# M33 register map
Registers are 32-bit, read-write, reset 0x0 unless marked. A register's access mark holds for its fields unless they carry their own. Offsets are from the block's base; lines under a group give offsets from that group; [hi:lo] are bit positions; {n}, {i} and the like mark numbered series; 'fields as' and 'values as' point back to an identical list; <NAME> marks a mode.

## Memory map
0xE000E010 STK size 0x11 — SysTick timer
0xE000E100 NVIC size 0x37D — Nested Vectored Interrupt Controller
0xE000EF34 FPU size 0xD — Floting point unit

## FPU — Floting point unit
Base 0xE000EF34
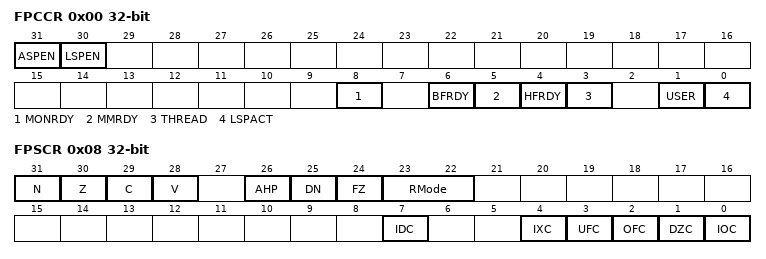
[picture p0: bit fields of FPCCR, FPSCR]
0x00 FPCCR — Floating-point context control register
  [31] ASPEN, [30] LSPEN, [8] MONRDY, [6] BFRDY, [5] MMRDY, [4] HFRDY, [3] THREAD, [1] USER, [0] LSPACT
0x04 FPCAR — Floating-point context address register
  [31:3] ADDRESS — Location of unpopulated floating-point
0x08 FPSCR — Floating-point status control register
  [31] N — Negative condition code flag
  [30] Z — Zero condition code flag
  [29] C — Carry condition code flag
  [28] V — Overflow condition code flag
  [26] AHP — Alternative half-precision control bit
  [25] DN — Default NaN mode control bit
  [24] FZ — Flush-to-zero mode control bit:
  [23:22] RMode — Rounding Mode control field
  [7] IDC — Input denormal cumulative exception bit.
  [4] IXC — Inexact cumulative exception bit
  [3] UFC — Underflow cumulative exception bit
  [2] OFC — Overflow cumulative exception bit
  [1] DZC — Division by zero cumulative exception bit.
  [0] IOC — Invalid operation cumulative exception bit

## NVIC — Nested Vectored Interrupt Controller
Base 0xE000E100
{0x0+4i} ISER{i} (i=0..2) — Interrupt Set-Enable Register
  [31:0] SETENA
0x0C ISER3 — Interrupt Set-Enable Register
{0x80+4i} ICER{i} (i=0..2) — Interrupt Clear-Enable Register
  [31:0] CLRENA
0x8C ICER3 — Interrupt Clear-Enable Register
{0x100+4i} ISPR{i} (i=0..2) — Interrupt Set-Pending Register
  [31:0] SETPEND
0x10C ISPR3 — Interrupt Set-Pending Register
{0x180+4i} ICPR{i} (i=0..2) — Interrupt Clear-Pending Register
  [31:0] CLRPEND
0x18C ICPR3 — Interrupt Clear-Pending Register
{0x200+4i} IABR{i} ro (i=0..2) — Interrupt Active Bit Register
  [31:0] ACTIVE
0x20C IABR3 — Interrupt Active Bit Register
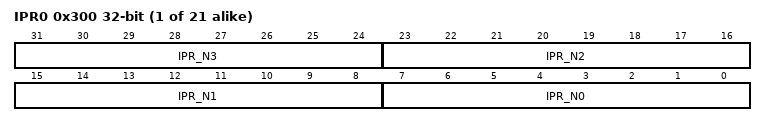
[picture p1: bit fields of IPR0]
{0x300+4i} IPR{i} (i=0..20) — Interrupt Priority Register
  [8n+7:8n] IPR_N{n} (n=0..3)
{0x300+4i} IPR{i} (i=21..29)

## STK — SysTick timer
Base 0xE000E010
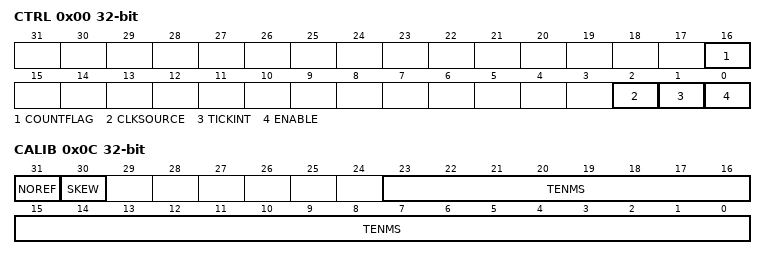
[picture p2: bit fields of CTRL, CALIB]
0x00 CTRL — SysTick control and status register
  [16] COUNTFLAG
  [2] CLKSOURCE — Clock source selection
  [1] TICKINT — SysTick exception request enable
  [0] ENABLE — Counter enable
0x04 LOAD — SysTick reload value register
  [23:0] RELOAD — RELOAD value
0x08 VAL — SysTick current value register
  [23:0] CURRENT — Current counter value
0x0C CALIB — SysTick calibration value register
  [31] NOREF — NOREF flag. Reads as zero
  [30] SKEW — SKEW flag: Indicates whether the TENMS value is exact
  [23:0] TENMS — Calibration value
